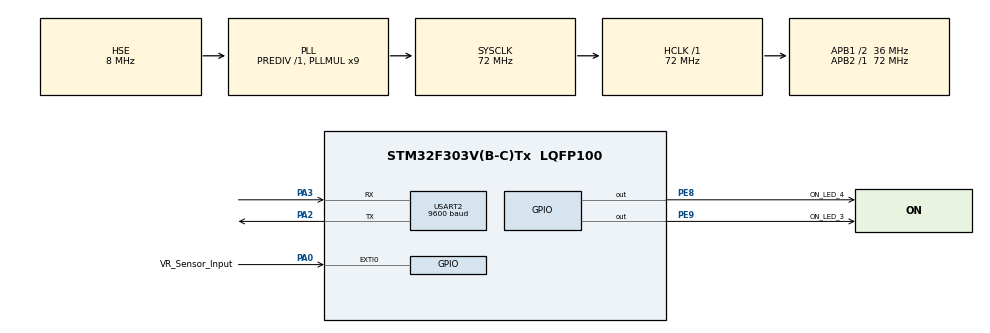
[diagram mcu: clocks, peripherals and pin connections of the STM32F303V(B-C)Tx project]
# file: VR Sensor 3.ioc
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Mcu.Family=STM32F3
Mcu.Name=STM32F303V(B-C)Tx
Mcu.Package=LQFP100
NVIC.EXTI0_IRQn=true\:0\:0\:false\:false\:true\:true
NVIC.PriorityGroup=NVIC_PRIORITYGROUP_4
NVIC.RCC_IRQn=true\:0\:0\:false\:false\:true\:true
NVIC.TIM3_IRQn=true\:0\:0\:false\:false\:true\:true
NVIC.USART2_IRQn=true\:0\:0\:false\:false\:true\:true
PA0.GPIO_Label=VR_Sensor_Input
PA0.GPIO_ModeDefaultEXTI=GPIO_MODE_IT_FALLING
PA0.GPIO_PuPd=GPIO_PULLUP
PA0.Signal=GPXTI0
PA13.Mode=Serial_Wire
PA13.Signal=SYS_JTMS-SWDIO
PA14.Mode=Serial_Wire
PA14.Signal=SYS_JTCK-SWCLK
PA2.Mode=Asynchronous
PA2.Signal=USART2_TX
PA3.Mode=Asynchronous
PA3.Signal=USART2_RX
PE8.GPIO_Label=ON_LED_4
PE8.PinState=GPIO_PIN_SET
PE8.Signal=GPIO_Output
PE9.GPIO_Label=ON_LED_3
PE9.PinState=GPIO_PIN_SET
PE9.Signal=GPIO_Output
PF0-OSC_IN.Mode=HSE-External-Oscillator
PF0-OSC_IN.Signal=RCC_OSC_IN
PF1-OSC_OUT.Mode=HSE-External-Oscillator
PF1-OSC_OUT.Signal=RCC_OSC_OUT
ProjectManager.HeapSize=0x200
ProjectManager.StackSize=0x400
ProjectManager.TargetToolchain=MDK-ARM V5
RCC.AHBFreq_Value=72000000
RCC.APB1CLKDivider=RCC_HCLK_DIV2
RCC.APB1Freq_Value=36000000
RCC.APB1TimFreq_Value=72000000
RCC.APB2Freq_Value=72000000
RCC.APB2TimFreq_Value=72000000
RCC.CortexFreq_Value=72000000
RCC.HCLKFreq_Value=72000000
RCC.HSE_VALUE=8000000
RCC.HSI_VALUE=8000000
RCC.LSE_VALUE=32768
RCC.PLLMUL=RCC_PLL_MUL9
RCC.PLLSourceVirtual=RCC_PLLSOURCE_HSE
RCC.SYSCLKFreq_VALUE=72000000
RCC.SYSCLKSourceVirtual=RCC_SYSCLKSOURCE_PLLCLK
RCC.USBFreq_Value=72000000
TIM3.AutoReloadPreload=TIM_AUTORELOAD_PRELOAD_DISABLE
TIM3.Period=2
TIM3.Prescaler=35999
USART2.BaudRate=9600
USART2.VirtualMode-Asynchronous=VM_ASYNC
VP_TIM3_VS_ClockSourceINT.Mode=Internal
board=custom

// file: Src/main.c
/* USER CODE BEGIN Header */
/**
  ******************************************************************************
  * @file           : main.c
  * @brief          : Main program body
  ******************************************************************************
  ** This notice applies to any and all portions of this file
  * that are not between comment pairs USER CODE BEGIN and
  * USER CODE END. Other portions of this file, whether
  * inserted by the user or by software development tools
  * are owned by their respective copyright owners.
  *
  * COPYRIGHT(c) 2018 STMicroelectronics
  *
  * Redistribution and use in source and binary forms, with or without modification,
  * are permitted provided that the following conditions are met:
  *   1. Redistributions of source code must retain the above copyright notice,
  *      this list of conditions and the following disclaimer.
  *   2. Redistributions in binary form must reproduce the above copyright notice,
  *      this list of conditions and the following disclaimer in the documentation
  *      and/or other materials provided with the distribution.
  *   3. Neither the name of STMicroelectronics nor the names of its contributors
  *      may be used to endorse or promote products derived from this software
  *      without specific prior written permission.
  *
  * THIS SOFTWARE IS PROVIDED BY THE COPYRIGHT HOLDERS AND CONTRIBUTORS "AS IS"
  * AND ANY EXPRESS OR IMPLIED WARRANTIES, INCLUDING, BUT NOT LIMITED TO, THE
  * IMPLIED WARRANTIES OF MERCHANTABILITY AND FITNESS FOR A PARTICULAR PURPOSE ARE
  * DISCLAIMED. IN NO EVENT SHALL THE COPYRIGHT HOLDER OR CONTRIBUTORS BE LIABLE
  * FOR ANY DIRECT, INDIRECT, INCIDENTAL, SPECIAL, EXEMPLARY, OR CONSEQUENTIAL
  * DAMAGES (INCLUDING, BUT NOT LIMITED TO, PROCUREMENT OF SUBSTITUTE GOODS OR
  * SERVICES; LOSS OF USE, DATA, OR PROFITS; OR BUSINESS INTERRUPTION) HOWEVER
  * CAUSED AND ON ANY THEORY OF LIABILITY, WHETHER IN CONTRACT, STRICT LIABILITY,
  * OR TORT (INCLUDING NEGLIGENCE OR OTHERWISE) ARISING IN ANY WAY OUT OF THE USE
  * OF THIS SOFTWARE, EVEN IF ADVISED OF THE POSSIBILITY OF SUCH DAMAGE.
  *
  ******************************************************************************
  */
/* USER CODE END Header */

#include "main.h"

TIM_HandleTypeDef htim3;

UART_HandleTypeDef huart2;

extern double velocidad;
extern double tiempo;
extern double posicion;
extern double delta_Tiempo;
extern double told;
extern int clicks;

void SystemClock_Config(void);
static void MX_GPIO_Init(void);
static void MX_TIM3_Init(void);
static void MX_USART2_UART_Init(void);

int main(void)
{

  /* MCU Configuration--------------------------------------------------------*/

  /* Reset of all peripherals, Initializes the Flash interface and the Systick. */
  HAL_Init();

  /* Configure the system clock */
  SystemClock_Config();

  /* Initialize all configured peripherals */
  MX_GPIO_Init();
  MX_TIM3_Init();
  MX_USART2_UART_Init();
  /* USER CODE BEGIN 2 */

	//Timer 3 intilialization
	HAL_TIM_Base_Start_IT(&htim3);

  /* USER CODE END 2 */

  /* Infinite loop */
  while (1)
  {

  }
}

void SystemClock_Config(void)
{
  RCC_OscInitTypeDef RCC_OscInitStruct = {0};
  RCC_ClkInitTypeDef RCC_ClkInitStruct = {0};
  RCC_PeriphCLKInitTypeDef PeriphClkInit = {0};

  /**Initializes the CPU, AHB and APB busses clocks
  */
  RCC_OscInitStruct.OscillatorType = RCC_OSCILLATORTYPE_HSE;
  RCC_OscInitStruct.HSEState = RCC_HSE_ON;
  RCC_OscInitStruct.HSEPredivValue = RCC_HSE_PREDIV_DIV1;
  RCC_OscInitStruct.HSIState = RCC_HSI_ON;
  RCC_OscInitStruct.PLL.PLLState = RCC_PLL_ON;
  RCC_OscInitStruct.PLL.PLLSource = RCC_PLLSOURCE_HSE;
  RCC_OscInitStruct.PLL.PLLMUL = RCC_PLL_MUL9;
  if (HAL_RCC_OscConfig(&RCC_OscInitStruct) != HAL_OK)
  {
    Error_Handler();
  }
  /**Initializes the CPU, AHB and APB busses clocks
  */
  RCC_ClkInitStruct.ClockType = RCC_CLOCKTYPE_HCLK|RCC_CLOCKTYPE_SYSCLK
                              |RCC_CLOCKTYPE_PCLK1|RCC_CLOCKTYPE_PCLK2;
  RCC_ClkInitStruct.SYSCLKSource = RCC_SYSCLKSOURCE_PLLCLK;
  RCC_ClkInitStruct.AHBCLKDivider = RCC_SYSCLK_DIV1;
  RCC_ClkInitStruct.APB1CLKDivider = RCC_HCLK_DIV2;
  RCC_ClkInitStruct.APB2CLKDivider = RCC_HCLK_DIV1;

  if (HAL_RCC_ClockConfig(&RCC_ClkInitStruct, FLASH_LATENCY_2) != HAL_OK)
  {
    Error_Handler();
  }
  PeriphClkInit.PeriphClockSelection = RCC_PERIPHCLK_USART2;
  PeriphClkInit.Usart2ClockSelection = RCC_USART2CLKSOURCE_PCLK1;
  if (HAL_RCCEx_PeriphCLKConfig(&PeriphClkInit) != HAL_OK)
  {
    Error_Handler();
  }
}

static void MX_TIM3_Init(void)
{

  TIM_ClockConfigTypeDef sClockSourceConfig = {0};
  TIM_MasterConfigTypeDef sMasterConfig = {0};

  htim3.Instance = TIM3;
  htim3.Init.Prescaler = 35999;
  htim3.Init.CounterMode = TIM_COUNTERMODE_UP;
  htim3.Init.Period = 2;
  htim3.Init.ClockDivision = TIM_CLOCKDIVISION_DIV1;
  htim3.Init.AutoReloadPreload = TIM_AUTORELOAD_PRELOAD_DISABLE;
  if (HAL_TIM_Base_Init(&htim3) != HAL_OK)
  {
    Error_Handler();
  }
  sClockSourceConfig.ClockSource = TIM_CLOCKSOURCE_INTERNAL;
  if (HAL_TIM_ConfigClockSource(&htim3, &sClockSourceConfig) != HAL_OK)
  {
    Error_Handler();
  }
  sMasterConfig.MasterOutputTrigger = TIM_TRGO_RESET;
  sMasterConfig.MasterSlaveMode = TIM_MASTERSLAVEMODE_DISABLE;
  if (HAL_TIMEx_MasterConfigSynchronization(&htim3, &sMasterConfig) != HAL_OK)
  {
    Error_Handler();
  }

}

static void MX_USART2_UART_Init(void)
{

  huart2.Instance = USART2;
  huart2.Init.BaudRate = 9600;
  huart2.Init.WordLength = UART_WORDLENGTH_8B;
  huart2.Init.StopBits = UART_STOPBITS_1;
  huart2.Init.Parity = UART_PARITY_NONE;
  huart2.Init.Mode = UART_MODE_TX_RX;
  huart2.Init.HwFlowCtl = UART_HWCONTROL_NONE;
  huart2.Init.OverSampling = UART_OVERSAMPLING_16;
  huart2.Init.OneBitSampling = UART_ONE_BIT_SAMPLE_DISABLE;
  huart2.AdvancedInit.AdvFeatureInit = UART_ADVFEATURE_NO_INIT;
  if (HAL_UART_Init(&huart2) != HAL_OK)
  {
    Error_Handler();
  }

}

static void MX_GPIO_Init(void)
{
  GPIO_InitTypeDef GPIO_InitStruct = {0};

  /* GPIO Ports Clock Enable */
  __HAL_RCC_GPIOF_CLK_ENABLE();
  __HAL_RCC_GPIOA_CLK_ENABLE();
  __HAL_RCC_GPIOE_CLK_ENABLE();

  /*Configure GPIO pin Output Level */
  //HAL_GPIO_WritePin(GPIOE, ON_LED_4_Pin|ON_LED_3_Pin, GPIO_PIN_SET);
	HAL_GPIO_WritePin(GPIOE, ON_LED_4_Pin, GPIO_PIN_SET);

  /*Configure GPIO pin : VR_Sensor_Input_Pin */
  GPIO_InitStruct.Pin = VR_Sensor_Input_Pin;
  GPIO_InitStruct.Mode = GPIO_MODE_IT_FALLING;
  GPIO_InitStruct.Pull = GPIO_PULLUP;
  HAL_GPIO_Init(VR_Sensor_Input_GPIO_Port, &GPIO_InitStruct);

  /*Configure GPIO pins : ON_LED_4_Pin ON_LED_3_Pin */
  GPIO_InitStruct.Pin = ON_LED_4_Pin|ON_LED_3_Pin;
  GPIO_InitStruct.Mode = GPIO_MODE_OUTPUT_PP;
  GPIO_InitStruct.Pull = GPIO_NOPULL;
  GPIO_InitStruct.Speed = GPIO_SPEED_FREQ_LOW;
  HAL_GPIO_Init(GPIOE, &GPIO_InitStruct);

  /* EXTI interrupt init*/
  HAL_NVIC_SetPriority(EXTI0_IRQn, 0, 0);
  HAL_NVIC_EnableIRQ(EXTI0_IRQn);

}

/* USER CODE BEGIN 4 */
void HAL_TIM_PeriodElapsedCallback(TIM_HandleTypeDef *htim){
	if(htim->Instance == TIM3){
		HAL_GPIO_TogglePin(GPIOE, GPIO_PIN_9);
		posicion  = tiempo*velocidad + posicion;
		tiempo = tiempo + 0.001; // Experimental time is approx 1.5 ms
	}
}
/* USER CODE END 4 */

void Error_Handler(void)
{
}

/************************ (C) COPYRIGHT STMicroelectronics *****END OF FILE****/
